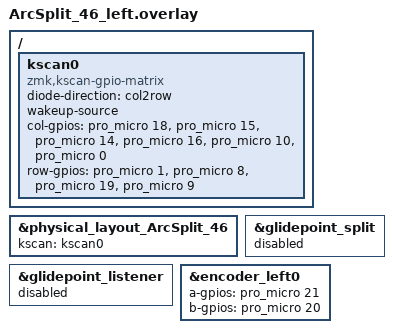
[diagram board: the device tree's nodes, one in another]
#include "ArcSplit_46.dtsi"

/ {
    kscan0: kscan0 {
        compatible = "zmk,kscan-gpio-matrix";
        diode-direction = "col2row";
        wakeup-source;

        col-gpios
            = <&pro_micro 18 GPIO_ACTIVE_HIGH>
            , <&pro_micro 15 GPIO_ACTIVE_HIGH>
            , <&pro_micro 14 GPIO_ACTIVE_HIGH>
            , <&pro_micro 16 GPIO_ACTIVE_HIGH>
            , <&pro_micro 10 GPIO_ACTIVE_HIGH>
            , <&pro_micro 0 GPIO_ACTIVE_HIGH>
            ;

        row-gpios
            = <&pro_micro 1 (GPIO_ACTIVE_HIGH | GPIO_PULL_DOWN)>
            , <&pro_micro 8 (GPIO_ACTIVE_HIGH | GPIO_PULL_DOWN)>
            , <&pro_micro 19 (GPIO_ACTIVE_HIGH | GPIO_PULL_DOWN)>
            , <&pro_micro 9 (GPIO_ACTIVE_HIGH | GPIO_PULL_DOWN)>
            ;
    };
};

&physical_layout_ArcSplit_46 {
    kscan = <&kscan0>;
};


&glidepoint_split {
    status = "disabled";   // change from "okay"
};

&glidepoint_listener {
    status = "disabled";   // change from "okay"
};

&encoder_left0 {
    a-gpios = <&pro_micro 21 (GPIO_ACTIVE_HIGH | GPIO_PULL_UP)>;
    b-gpios = <&pro_micro 20 (GPIO_ACTIVE_HIGH | GPIO_PULL_UP)>;
    status = "okay";
};
